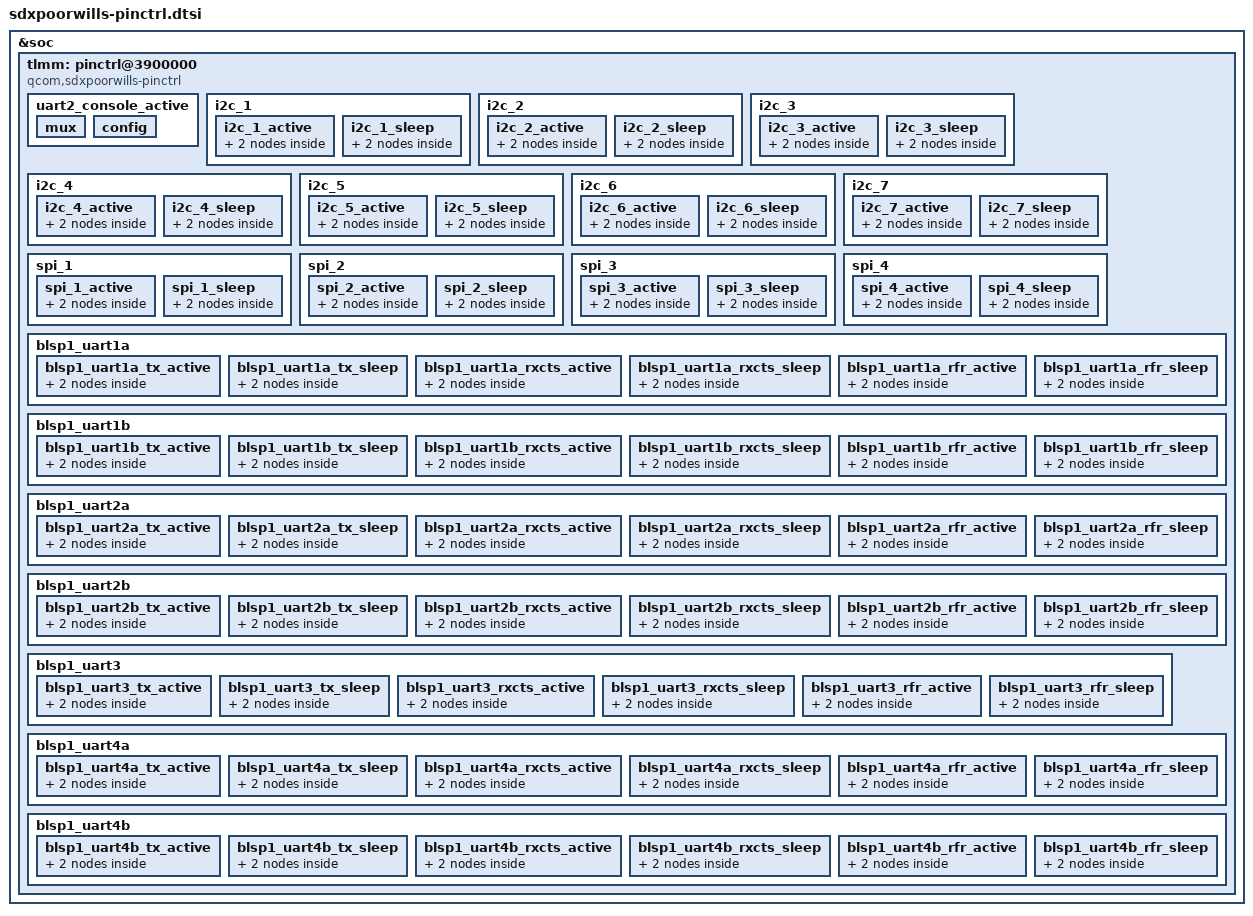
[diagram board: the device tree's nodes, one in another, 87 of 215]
/* Copyright (c) 2017, The Linux Foundation. All rights reserved.
 *
 * This program is free software; you can redistribute it and/or modify
 * it under the terms of the GNU General Public License version 2 and
 * only version 2 as published by the Free Software Foundation.
 *
 * This program is distributed in the hope that it will be useful,
 * but WITHOUT ANY WARRANTY; without even the implied warranty of
 * MERCHANTABILITY or FITNESS FOR A PARTICULAR PURPOSE.  See the
 * GNU General Public License for more details.
 */

&soc {
	tlmm: pinctrl@3900000 {
		compatible = "qcom,sdxpoorwills-pinctrl";
		reg = <0x3900000 0x300000>;
		interrupts = <0 212 0>;
		gpio-controller;
		#gpio-cells = <2>;
		interrupt-controller;
		#interrupt-cells = <2>;

		uart2_console_active: uart2_console_active {
			mux {
				pins = "gpio4", "gpio5";
				function = "blsp_uart2";
			};
			config {
				pins = "gpio4", "gpio5";
				drive-strength = <2>;
				bias-disable;
			};
		};

		/* I2C CONFIGURATION */
		i2c_1 {
			i2c_1_active: i2c_1_active {
				mux {
					pins = "gpio2", "gpio3";
					function = "blsp_i2c1";
				};

				config {
					pins = "gpio2", "gpio3";
					drive-strength = <2>;
					bias-disable;
				};
			};

			i2c_1_sleep: i2c_1_sleep {
				mux {
					pins = "gpio2", "gpio3";
					function = "blsp_i2c1";
				};

				config {
					pins = "gpio2", "gpio3";
					drive-strength = <2>;
					bias-pull-up;
				};
			};
		};

		i2c_2 {
			i2c_2_active: i2c_2_active {
				mux {
					pins = "gpio6", "gpio7";
					function = "blsp_i2c2";
				};

				config {
					pins = "gpio6", "gpio7";
					drive-strength = <2>;
					bias-disable;
				};
			};

			i2c_2_sleep: i2c_2_sleep {
				mux {
					pins = "gpio6", "gpio7";
					function = "blsp_i2c2";
				};

				config {
					pins = "gpio6", "gpio7";
					drive-strength = <2>;
					bias-pull-up;
				};
			};
		};

		i2c_3 {
			i2c_3_active: i2c_3_active {
				mux {
					pins = "gpio10", "gpio11";
					function = "blsp_i2c3";
				};

				config {
					pins = "gpio10", "gpio11";
					drive-strength = <2>;
					bias-disable;
				};
			};

			i2c_3_sleep: i2c_3_sleep {
				mux {
					pins = "gpio10", "gpio11";
					function = "blsp_i2c3";
				};

				config {
					pins = "gpio10", "gpio11";
					drive-strength = <2>;
					bias-pull-up;
				};
			};
		};

		i2c_4 {
			i2c_4_active: i2c_4_active {
				mux {
					pins = "gpio76", "gpio77";
					function = "blsp_i2c4";
				};

				config {
					pins = "gpio76", "gpio77";
					drive-strength = <2>;
					bias-disable;
				};
			};

			i2c_4_sleep: i2c_4_sleep {
				mux {
					pins = "gpio76", "gpio77";
					function = "blsp_i2c4";
				};

				config {
					pins = "gpio76", "gpio77";
					drive-strength = <2>;
					bias-pull-up;
				};
			};
		};

		i2c_5 {
			i2c_5_active: i2c_5_active {
				mux {
					pins = "gpio74", "gpio75";
					function = "blsp_i2c1";
				};

				config {
					pins = "gpio74", "gpio75";
					drive-strength = <2>;
					bias-disable;
				};
			};

			i2c_5_sleep: i2c_5_sleep {
				mux {
					pins = "gpio74", "gpio75";
					function = "blsp_i2c1";
				};

				config {
					pins = "gpio74", "gpio75";
					drive-strength = <2>;
					bias-pull-up;
				};
			};
		};

		i2c_6 {
			i2c_6_active: i2c_6_active {
				mux {
					pins = "gpio65", "gpio66";
					function = "blsp_i2c2";
				};

				config {
					pins = "gpio65", "gpio66";
					drive-strength = <2>;
					bias-disable;
				};
			};

			i2c_6_sleep: i2c_6_sleep {
				mux {
					pins = "gpio65", "gpio66";
					function = "blsp_i2c2";
				};

				config {
					pins = "gpio65", "gpio66";
					drive-strength = <2>;
					bias-pull-up;
				};
			};
		};

		i2c_7 {
			i2c_7_active: i2c_7_active {
				mux {
					pins = "gpio18", "gpio19";
					function = "blsp_i2c4";
				};

				config {
					pins = "gpio18", "gpio19";
					drive-strength = <2>;
					bias-disable;
				};
			};

			i2c_7_sleep: i2c_7_sleep {
				mux {
					pins = "gpio18", "gpio19";
					function = "blsp_i2c4";
				};

				config {
					pins = "gpio18", "gpio19";
					drive-strength = <2>;
					bias-pull-up;
				};
			};
		};

		/* SPI CONFIGURATION */
		spi_1 {
			spi_1_active: spi_1_active {
				mux {
					pins = "gpio72", "gpio73",
							"gpio74", "gpio75";
					function = "blsp_spi1";
				};

				config {
					pins = "gpio72", "gpio73",
							"gpio74", "gpio75";
					drive-strength = <6>;
					bias-disable;
				};
			};

			spi_1_sleep: spi_1_sleep {
				mux {
					pins = "gpio72", "gpio73",
							"gpio74", "gpio75";
					function = "blsp_spi1";
				};

				config {
					pins = "gpio72", "gpio73",
							"gpio74", "gpio75";
					drive-strength = <6>;
					bias-disable;
				};
			};
		};

		spi_2 {
			spi_2_active: spi_2_active {
				mux {
					pins = "gpio4", "gpio5",
							"gpio6", "gpio7";
					function = "blsp_spi2";
				};

				config {
					pins = "gpio4", "gpio5",
							"gpio6", "gpio7";
					drive-strength = <6>;
					bias-disable;
				};
			};

			spi_2_sleep: spi_2_sleep {
				mux {
					pins = "gpio4", "gpio5",
							"gpio6", "gpio7";
					function = "blsp_spi2";
				};

				config {
					pins = "gpio4", "gpio5",
							"gpio6", "gpio7";
					drive-strength = <6>;
					bias-disable;
				};
			};
		};

		spi_3 {
			spi_3_active: spi_3_active {
				mux {
					pins = "gpio8", "gpio9",
							"gpio10", "gpio11";
					function = "blsp_spi3";
				};

				config {
					pins = "gpio8", "gpio9",
							"gpio10", "gpio11";
					drive-strength = <6>;
					bias-disable;
				};
			};

			spi_3_sleep: spi_3_sleep {
				mux {
					pins = "gpio8", "gpio9",
							"gpio10", "gpio11";
					function = "blsp_spi3";
				};

				config {
					pins = "gpio8", "gpio9",
							"gpio10", "gpio11";
					drive-strength = <6>;
					bias-disable;
				};
			};
		};

		spi_4 {
			spi_4_active: spi_4_active {
				mux {
					pins = "gpio16", "gpio17",
							"gpio18", "gpio19";
					function = "blsp_spi4";
				};

				config {
					pins = "gpio16", "gpio17",
							"gpio18", "gpio19";
					drive-strength = <6>;
					bias-disable;
				};
			};

			spi_4_sleep: spi_4_sleep {
				mux {
					pins = "gpio16", "gpio17",
							"gpio18", "gpio19";
					function = "blsp_spi4";
				};

				config {
					pins = "gpio16", "gpio17",
							"gpio18", "gpio19";
					drive-strength = <6>;
					bias-disable;
				};
			};
		};

		/* HS UART CONFIGURATION */

		blsp1_uart1a: blsp1_uart1a {
			blsp1_uart1a_tx_active: blsp1_uart1a_tx_active {
				mux {
					pins = "gpio0";
					function = "blsp_uart1";
				};

				config {
					pins = "gpio0";
					drive-strength = <2>;
					bias-disable;
				};
			};

			blsp1_uart1a_tx_sleep: blsp1_uart1a_tx_sleep {
				mux {
					pins = "gpio0";
					function = "gpio";
				};

				config {
					pins = "gpio0";
					drive-strength = <2>;
					bias-pull-up;
				};
			};

			blsp1_uart1a_rxcts_active: blsp1_uart1a_rxcts_active {
				mux {
					pins = "gpio1", "gpio2";
					function = "blsp_uart1";
				};

				config {
					pins = "gpio1", "gpio2";
					drive-strength = <2>;
					bias-disable;
				};
			};

			blsp1_uart1a_rxcts_sleep: blsp1_uart1a_rxcts_sleep {
				mux {
					pins = "gpio1", "gpio2";
					function = "gpio";
				};

				config {
					pins = "gpio1", "gpio2";
					drive-strength = <2>;
					bias-no-pull;
				};
			};

			blsp1_uart1a_rfr_active: blsp1_uart1a_rfr_active {
				mux {
					pins = "gpio3";
					function = "blsp_uart1";
				};

				config {
					pins = "gpio3";
					drive-strength = <2>;
					bias-disable;
				};
			};

			blsp1_uart1a_rfr_sleep: blsp1_uart1a_rfr_sleep {
				mux {
					pins = "gpio3";
					function = "gpio";
				};

				config {
					pins = "gpio3";
					drive-strength = <2>;
					bias-no-pull;
				};
			};
		};

		blsp1_uart1b: blsp1_uart1b {
			blsp1_uart1b_tx_active: blsp1_uart1b_tx_active {
				mux {
					pins = "gpio20";
					function = "blsp_uart1";
				};

				config {
					pins = "gpio20";
					drive-strength = <2>;
					bias-disable;
				};
			};

			blsp1_uart1b_tx_sleep: blsp1_uart1b_tx_sleep {
				mux {
					pins = "gpio20";
					function = "gpio";
				};

				config {
					pins = "gpio20";
					drive-strength = <2>;
					bias-pull-up;
				};
			};

			blsp1_uart1b_rxcts_active: blsp1_uart1b_rxcts_active {
				mux {
					pins = "gpio21", "gpio22";
					function = "blsp_uart1";
				};

				config {
					pins = "gpio21", "gpio22";
					drive-strength = <2>;
					bias-disable;
				};
			};

			blsp1_uart1b_rxcts_sleep: blsp1_uart1b_rxcts_sleep {
				mux {
					pins = "gpio21", "gpio22";
					function = "gpio";
				};

				config {
					pins = "gpio21", "gpio22";
					drive-strength = <2>;
					bias-no-pull;
				};
			};

			blsp1_uart1b_rfr_active: blsp1_uart1b_rfr_active {
				mux {
					pins = "gpio23";
					function = "blsp_uart1";
				};

				config {
					pins = "gpio23";
					drive-strength = <2>;
					bias-disable;
				};
			};

			blsp1_uart1b_rfr_sleep: blsp1_uart1b_rfr_sleep {
				mux {
					pins = "gpio23";
					function = "gpio";
				};

				config {
					pins = "gpio23";
					drive-strength = <2>;
					bias-no-pull;
				};
			};
		};

		blsp1_uart2a: blsp1_uart2a {
			blsp1_uart2a_tx_active: blsp1_uart2a_tx_active {
				mux {
					pins = "gpio4";
					function = "blsp_uart2";
				};

				config {
					pins = "gpio4";
					drive-strength = <2>;
					bias-disable;
				};
			};

			blsp1_uart2a_tx_sleep: blsp1_uart2a_tx_sleep {
				mux {
					pins = "gpio4";
					function = "gpio";
				};

				config {
					pins = "gpio4";
					drive-strength = <2>;
					bias-pull-up;
				};
			};

			blsp1_uart2a_rxcts_active: blsp1_uart2a_rxcts_active {
				mux {
					pins = "gpio5", "gpio6";
					function = "blsp_uart2";
				};

				config {
					pins = "gpio5", "gpio6";
					drive-strength = <2>;
					bias-disable;
				};
			};

			blsp1_uart2a_rxcts_sleep: blsp1_uart2a_rxcts_sleep {
				mux {
					pins = "gpio5", "gpio6";
					function = "gpio";
				};

				config {
					pins = "gpio1", "gpio2";
					drive-strength = <2>;
					bias-no-pull;
				};
			};

			blsp1_uart2a_rfr_active: blsp1_uart2a_rfr_active {
				mux {
					pins = "gpio7";
					function = "blsp_uart2";
				};

				config {
					pins = "gpio7";
					drive-strength = <2>;
					bias-disable;
				};
			};

			blsp1_uart2a_rfr_sleep: blsp1_uart2a_rfr_sleep {
				mux {
					pins = "gpio7";
					function = "gpio";
				};

				config {
					pins = "gpio7";
					drive-strength = <2>;
					bias-no-pull;
				};
			};
		};

		blsp1_uart2b: blsp1_uart2b {
			blsp1_uart2b_tx_active: blsp1_uart2b_tx_active {
				mux {
					pins = "gpio63";
					function = "blsp_uart2";
				};

				config {
					pins = "gpio63";
					drive-strength = <2>;
					bias-disable;
				};
			};

			blsp1_uart2b_tx_sleep: blsp1_uart2b_tx_sleep {
				mux {
					pins = "gpio63";
					function = "gpio";
				};

				config {
					pins = "gpio63";
					drive-strength = <2>;
					bias-pull-up;
				};
			};

			blsp1_uart2b_rxcts_active: blsp1_uart2b_rxcts_active {
				mux {
					pins = "gpio64", "gpio65";
					function = "blsp_uart2";
				};

				config {
					pins = "gpio64", "gpio65";
					drive-strength = <2>;
					bias-disable;
				};
			};

			blsp1_uart2b_rxcts_sleep: blsp1_uart2b_rxcts_sleep {
				mux {
					pins = "gpio64", "gpio65";
					function = "gpio";
				};

				config {
					pins = "gpio64", "gpio65";
					drive-strength = <2>;
					bias-no-pull;
				};
			};

			blsp1_uart2b_rfr_active: blsp1_uart2b_rfr_active {
				mux {
					pins = "gpio66";
					function = "blsp_uart2";
				};

				config {
					pins = "gpio66";
					drive-strength = <2>;
					bias-disable;
				};
			};

			blsp1_uart2b_rfr_sleep: blsp1_uart2b_rfr_sleep {
				mux {
					pins = "gpio66";
					function = "gpio";
				};

				config {
					pins = "gpio66";
					drive-strength = <2>;
					bias-no-pull;
				};
			};
		};

		blsp1_uart3: blsp1_uart3 {
			blsp1_uart3_tx_active: blsp1_uart3_tx_active {
				mux {
					pins = "gpio8";
					function = "blsp_uart3";
				};

				config {
					pins = "gpio8";
					drive-strength = <2>;
					bias-disable;
				};
			};

			blsp1_uart3_tx_sleep: blsp1_uart3_tx_sleep {
				mux {
					pins = "gpio8";
					function = "gpio";
				};

				config {
					pins = "gpio8";
					drive-strength = <2>;
					bias-pull-up;
				};
			};

			blsp1_uart3_rxcts_active: blsp1_uart3_rxcts_active {
				mux {
					pins = "gpio9", "gpio10";
					function = "blsp_uart3";
				};

				config {
					pins = "gpio9", "gpio10";
					drive-strength = <2>;
					bias-disable;
				};
			};

			blsp1_uart3_rxcts_sleep: blsp1_uart3_rxcts_sleep {
				mux {
					pins = "gpio9", "gpio10";
					function = "gpio";
				};

				config {
					pins = "gpio9", "gpio10";
					drive-strength = <2>;
					bias-no-pull;
				};
			};

			blsp1_uart3_rfr_active: blsp1_uart3_rfr_active {
				mux {
					pins = "gpio11";
					function = "blsp_uart3";
				};

				config {
					pins = "gpio11";
					drive-strength = <2>;
					bias-disable;
				};
			};

			blsp1_uart3_rfr_sleep: blsp1_uart3_rfr_sleep {
				mux {
					pins = "gpio11";
					function = "gpio";
				};

				config {
					pins = "gpio11";
					drive-strength = <2>;
					bias-no-pull;
				};
			};
		};

		blsp1_uart4a: blsp1_uart4a {
			blsp1_uart4a_tx_active: blsp1_uart4a_tx_active {
				mux {
					pins = "gpio20";
					function = "blsp_uart4";
				};

				config {
					pins = "gpio20";
					drive-strength = <2>;
					bias-disable;
				};
			};

			blsp1_uart4a_tx_sleep: blsp1_uart4a_tx_sleep {
				mux {
					pins = "gpio20";
					function = "gpio";
				};

				config {
					pins = "gpio20";
					drive-strength = <2>;
					bias-pull-up;
				};
			};

			blsp1_uart4a_rxcts_active: blsp1_uart4a_rxcts_active {
				mux {
					pins = "gpio21", "gpio22";
					function = "blsp_uart4";
				};

				config {
					pins = "gpio21", "gpio22";
					drive-strength = <2>;
					bias-disable;
				};
			};

			blsp1_uart4a_rxcts_sleep: blsp1_uart4a_rxcts_sleep {
				mux {
					pins = "gpio21", "gpio22";
					function = "gpio";
				};

				config {
					pins = "gpio21", "gpio22";
					drive-strength = <2>;
					bias-no-pull;
				};
			};

			blsp1_uart4a_rfr_active: blsp1_uart4a_rfr_active {
				mux {
					pins = "gpio23";
					function = "blsp_uart4";
				};

				config {
					pins = "gpio23";
					drive-strength = <2>;
					bias-disable;
				};
			};

			blsp1_uart4a_rfr_sleep: blsp1_uart4a_rfr_sleep {
				mux {
					pins = "gpio23";
					function = "gpio";
				};

				config {
					pins = "gpio23";
					drive-strength = <2>;
					bias-no-pull;
				};
			};
		};

		blsp1_uart4b: blsp1_uart4b {
			blsp1_uart4b_tx_active: blsp1_uart4b_tx_active {
				mux {
					pins = "gpio16";
					function = "blsp_uart4";
				};

				config {
					pins = "gpio16";
					drive-strength = <2>;
					bias-disable;
				};
			};

			blsp1_uart4b_tx_sleep: blsp1_uart4b_tx_sleep {
				mux {
					pins = "gpio16";
					function = "gpio";
				};

				config {
					pins = "gpio16";
					drive-strength = <2>;
					bias-pull-up;
				};
			};

			blsp1_uart4b_rxcts_active: blsp1_uart4b_rxcts_active {
				mux {
					pins = "gpio17", "gpio18";
					function = "blsp_uart4";
				};

				config {
					pins = "gpio17", "gpio18";
					drive-strength = <2>;
					bias-disable;
				};
			};

			blsp1_uart4b_rxcts_sleep: blsp1_uart4b_rxcts_sleep {
				mux {
					pins = "gpio17", "gpio18";
					function = "gpio";
				};

				config {
					pins = "gpio17", "gpio18";
					drive-strength = <2>;
					bias-no-pull;
				};
			};

			blsp1_uart4b_rfr_active: blsp1_uart4b_rfr_active {
				mux {
					pins = "gpio19";
					function = "blsp_uart4";
				};

				config {
					pins = "gpio19";
					drive-strength = <2>;
					bias-disable;
				};
			};

			blsp1_uart4b_rfr_sleep: blsp1_uart4b_rfr_sleep {
				mux {
					pins = "gpio19";
					function = "gpio";
				};

				config {
					pins = "gpio19";
					drive-strength = <2>;
					bias-no-pull;
				};
			};
		};
	};
};
